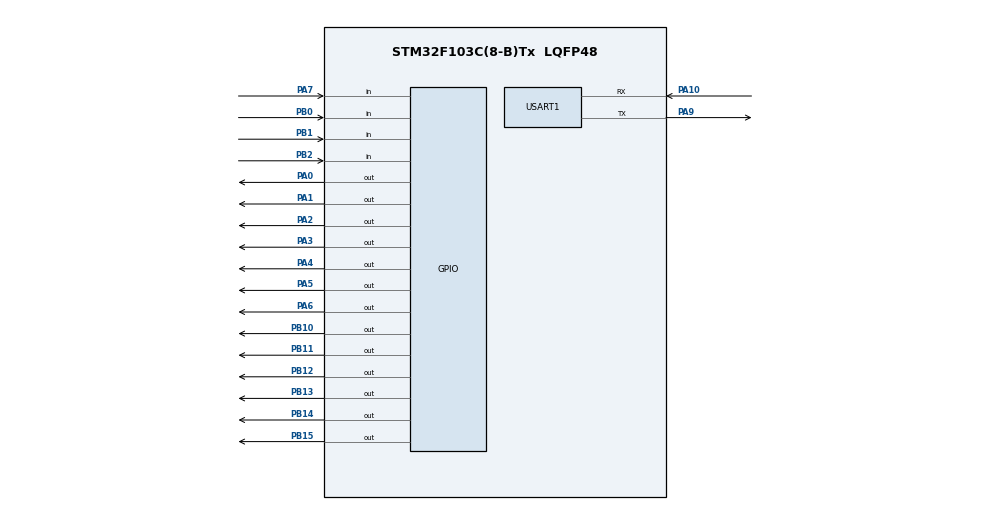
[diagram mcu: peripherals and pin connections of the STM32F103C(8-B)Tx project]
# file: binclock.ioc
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Mcu.Family=STM32F1
Mcu.Name=STM32F103C(8-B)Tx
Mcu.Package=LQFP48
NVIC.PriorityGroup=NVIC_PRIORITYGROUP_4
PA0-WKUP.Signal=GPIO_Output
PA1.Signal=GPIO_Output
PA10.Mode=Asynchronous
PA10.Signal=USART1_RX
PA13.Mode=Serial_Wire
PA13.Signal=SYS_JTMS-SWDIO
PA14.Mode=Serial_Wire
PA14.Signal=SYS_JTCK-SWCLK
PA2.Signal=GPIO_Output
PA3.Signal=GPIO_Output
PA4.Signal=GPIO_Output
PA5.Signal=GPIO_Output
PA6.Signal=GPIO_Output
PA7.GPIO_PuPd=GPIO_PULLDOWN
PA7.Signal=GPIO_Input
PA9.Mode=Asynchronous
PA9.Signal=USART1_TX
PB0.GPIO_PuPd=GPIO_PULLDOWN
PB0.Signal=GPIO_Input
PB1.GPIO_PuPd=GPIO_PULLDOWN
PB1.Signal=GPIO_Input
PB10.Signal=GPIO_Output
PB11.Signal=GPIO_Output
PB12.Signal=GPIO_Output
PB13.Signal=GPIO_Output
PB14.Signal=GPIO_Output
PB15.Signal=GPIO_Output
PB2.GPIO_PuPd=GPIO_PULLDOWN
PB2.Signal=GPIO_Input
PC14-OSC32_IN.Mode=LSE-External-Oscillator
PC14-OSC32_IN.Signal=RCC_OSC32_IN
PC15-OSC32_OUT.Mode=LSE-External-Oscillator
PC15-OSC32_OUT.Signal=RCC_OSC32_OUT
ProjectManager.HeapSize=0x200
ProjectManager.StackSize=0x400
ProjectManager.TargetToolchain=SW4STM32
RCC.ClockTypeHCLK=RCC_CLOCKTYPE_HCLK
RCC.ClockTypePCLK1=RCC_CLOCKTYPE_PCLK1
RCC.ClockTypePCLK2=RCC_CLOCKTYPE_PCLK2
RCC.EnableHSE=false
RCC.EnableHSERTCDevisor=false
RCC.EnableLSE=true
RCC.EnableLSERTC=true
RCC.EnableMCOMultDivisor=false
RCC.HSEState=RCC_HSE_OFF
RCC.HSIState=RCC_HSI_ON
RCC.IWDGEnable=false
RCC.LSEState=RCC_LSE_ON
RCC.LSIState=RCC_LSI_OFF
RCC.MCOEnable=false
RCC.OscillatorTypeHSI=RCC_OSCILLATORTYPE_HSI
RCC.OscillatorTypeLSE=RCC_OSCILLATORTYPE_LSE
RCC.PLLSource=RCC_PLLSOURCE_HSI_DIV2
RCC.PLLState=RCC_PLL_OFF
RCC.RCC_PERIPHCLK_RTCVar=RCC_PERIPHCLK_RTC
RCC.RTCClockSelection=RCC_RTCCLKSOURCE_LSE
RCC.RTCEnable=true
USART1.HwFlowCtl-Asynchronous=UART_HWCONTROL_NONE
USART1.VirtualMode=VM_ASYNC
VP_RTC_VS_RTC_Activate.Mode=RTC_Enabled
board=binclock

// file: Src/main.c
/**
  ******************************************************************************
  * File Name          : main.c
  * Description        : Main program body
  ******************************************************************************
  *
  * COPYRIGHT(c) 2017 STMicroelectronics
  *
  * Redistribution and use in source and binary forms, with or without modification,
  * are permitted provided that the following conditions are met:
  *   1. Redistributions of source code must retain the above copyright notice,
  *      this list of conditions and the following disclaimer.
  *   2. Redistributions in binary form must reproduce the above copyright notice,
  *      this list of conditions and the following disclaimer in the documentation
  *      and/or other materials provided with the distribution.
  *   3. Neither the name of STMicroelectronics nor the names of its contributors
  *      may be used to endorse or promote products derived from this software
  *      without specific prior written permission.
  *
  * THIS SOFTWARE IS PROVIDED BY THE COPYRIGHT HOLDERS AND CONTRIBUTORS "AS IS"
  * AND ANY EXPRESS OR IMPLIED WARRANTIES, INCLUDING, BUT NOT LIMITED TO, THE
  * IMPLIED WARRANTIES OF MERCHANTABILITY AND FITNESS FOR A PARTICULAR PURPOSE ARE
  * DISCLAIMED. IN NO EVENT SHALL THE COPYRIGHT HOLDER OR CONTRIBUTORS BE LIABLE
  * FOR ANY DIRECT, INDIRECT, INCIDENTAL, SPECIAL, EXEMPLARY, OR CONSEQUENTIAL
  * DAMAGES (INCLUDING, BUT NOT LIMITED TO, PROCUREMENT OF SUBSTITUTE GOODS OR
  * SERVICES; LOSS OF USE, DATA, OR PROFITS; OR BUSINESS INTERRUPTION) HOWEVER
  * CAUSED AND ON ANY THEORY OF LIABILITY, WHETHER IN CONTRACT, STRICT LIABILITY,
  * OR TORT (INCLUDING NEGLIGENCE OR OTHERWISE) ARISING IN ANY WAY OUT OF THE USE
  * OF THIS SOFTWARE, EVEN IF ADVISED OF THE POSSIBILITY OF SUCH DAMAGE.
  *
  ******************************************************************************
  */
#include "main.h"
#include "stm32f1xx_hal.h"
#include "rtc.h"
#include "usart.h"
#include "gpio.h"

/* USER CODE BEGIN Includes */
#include "clock.h"
/* USER CODE END Includes */

/* USER CODE BEGIN PV */
/* Private variables ---------------------------------------------------------*/

/* USER CODE END PV */

void SystemClock_Config(void);
void Error_Handler(void);

/* USER CODE BEGIN PFP */
/* Private function prototypes -----------------------------------------------*/

/* USER CODE END PFP */

int main(void)
{

  /* MCU Configuration----------------------------------------------------------*/

  /* Reset of all peripherals, Initializes the Flash interface and the Systick. */
  HAL_Init();

  /* Configure the system clock */
  SystemClock_Config();

  /* Initialize all configured peripherals */
  MX_GPIO_Init();
  MX_USART1_UART_Init();
  MX_RTC_Init();

  /* USER CODE BEGIN 2 */
  printf("HELLO\n");
  HAL_GPIO_WritePin(GPIOA, GPIO_PIN_0, GPIO_PIN_SET);
  clock_init();
  /* USER CODE END 2 */

  /* Infinite loop */
  /* USER CODE BEGIN WHILE */
  while (1)
  {
      clock_upd();
//      printf("%d:%d:%d\n", time.Hours, time.Minutes, time.Seconds);
//      HAL_GPIO_WritePin(GPIOA, GPIO_PIN_0, GPIO_PIN_RESET);
//      HAL_Delay(100);
//      HAL_GPIO_WritePin(GPIOA, GPIO_PIN_0, GPIO_PIN_SET);
      HAL_Delay(10);
  /* USER CODE END WHILE */

  }

}

/** System Clock Configuration
*/
void SystemClock_Config(void)
{

  RCC_OscInitTypeDef RCC_OscInitStruct;
  RCC_ClkInitTypeDef RCC_ClkInitStruct;
  RCC_PeriphCLKInitTypeDef PeriphClkInit;

    /**Initializes the CPU, AHB and APB busses clocks
    */
  RCC_OscInitStruct.OscillatorType = RCC_OSCILLATORTYPE_HSI|RCC_OSCILLATORTYPE_LSE;
  RCC_OscInitStruct.LSEState = RCC_LSE_ON;
  RCC_OscInitStruct.HSIState = RCC_HSI_ON;
  RCC_OscInitStruct.HSICalibrationValue = 16;
  RCC_OscInitStruct.PLL.PLLState = RCC_PLL_NONE;
  if (HAL_RCC_OscConfig(&RCC_OscInitStruct) != HAL_OK)
  {
    Error_Handler();
  }

    /**Initializes the CPU, AHB and APB busses clocks
    */
  RCC_ClkInitStruct.ClockType = RCC_CLOCKTYPE_HCLK|RCC_CLOCKTYPE_SYSCLK
                              |RCC_CLOCKTYPE_PCLK1|RCC_CLOCKTYPE_PCLK2;
  RCC_ClkInitStruct.SYSCLKSource = RCC_SYSCLKSOURCE_HSI;
  RCC_ClkInitStruct.AHBCLKDivider = RCC_SYSCLK_DIV1;
  RCC_ClkInitStruct.APB1CLKDivider = RCC_HCLK_DIV1;
  RCC_ClkInitStruct.APB2CLKDivider = RCC_HCLK_DIV1;

  if (HAL_RCC_ClockConfig(&RCC_ClkInitStruct, FLASH_LATENCY_0) != HAL_OK)
  {
    Error_Handler();
  }

  PeriphClkInit.PeriphClockSelection = RCC_PERIPHCLK_RTC;
  PeriphClkInit.RTCClockSelection = RCC_RTCCLKSOURCE_LSE;
  if (HAL_RCCEx_PeriphCLKConfig(&PeriphClkInit) != HAL_OK)
  {
    Error_Handler();
  }

    /**Configure the Systick interrupt time
    */
  HAL_SYSTICK_Config(HAL_RCC_GetHCLKFreq()/1000);

    /**Configure the Systick
    */
  HAL_SYSTICK_CLKSourceConfig(SYSTICK_CLKSOURCE_HCLK);

  /* SysTick_IRQn interrupt configuration */
  HAL_NVIC_SetPriority(SysTick_IRQn, 0, 0);
}

void Error_Handler(void)
{
  while(1)
  {
  }
}

/************************ (C) COPYRIGHT STMicroelectronics *****END OF FILE****/
